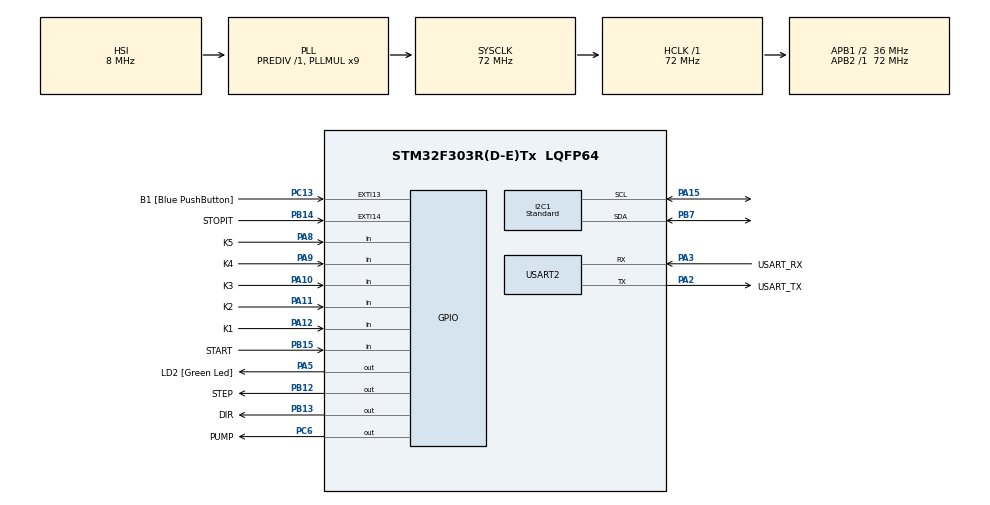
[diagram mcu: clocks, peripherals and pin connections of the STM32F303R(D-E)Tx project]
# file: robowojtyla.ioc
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FREERTOS.Tasks01=defaultTask,24,128,StartDefaultTask,Default,NULL,Dynamic,NULL,NULL;robotOne,24,128,startRobotOne,As external,NULL,Dynamic,NULL,NULL
I2C1.I2C_Speed_Mode=I2C_Standard
Mcu.Family=STM32F3
Mcu.Name=STM32F303R(D-E)Tx
Mcu.Package=LQFP64
NVIC.EXTI15_10_IRQn=true\:5\:0\:false\:false\:true\:true\:true\:true\:true
NVIC.PriorityGroup=NVIC_PRIORITYGROUP_4
NVIC.TIM1_TRG_COM_TIM17_IRQn=true\:15\:0\:false\:false\:true\:false\:false\:true\:true
NVIC.TimeBase=TIM1_TRG_COM_TIM17_IRQn
NVIC.TimeBaseIP=TIM17
PA10.GPIO_Label=K3
PA10.Signal=GPIO_Input
PA11.GPIO_Label=K2
PA11.Signal=GPIO_Input
PA12.GPIO_Label=K1
PA12.Signal=GPIO_Input
PA13.GPIO_Label=TMS
PA13.Mode=Serial_Wire
PA13.Signal=SYS_JTMS-SWDIO
PA14.GPIO_Label=TCK
PA14.Mode=Serial_Wire
PA14.Signal=SYS_JTCK-SWCLK
PA15.Mode=I2C
PA15.Signal=I2C1_SCL
PA2.GPIO_Label=USART_TX
PA2.GPIO_Mode=GPIO_MODE_AF_PP
PA2.GPIO_PuPd=GPIO_NOPULL
PA2.GPIO_Speed=GPIO_SPEED_FREQ_LOW
PA2.Mode=Asynchronous
PA2.Signal=USART2_TX
PA3.GPIO_Label=USART_RX
PA3.GPIO_Mode=GPIO_MODE_AF_PP
PA3.GPIO_PuPd=GPIO_NOPULL
PA3.GPIO_Speed=GPIO_SPEED_FREQ_LOW
PA3.Mode=Asynchronous
PA3.Signal=USART2_RX
PA5.GPIO_Label=LD2 [Green Led]
PA5.GPIO_Mode=GPIO_MODE_OUTPUT_PP
PA5.GPIO_PuPd=GPIO_NOPULL
PA5.GPIO_Speed=GPIO_SPEED_FREQ_LOW
PA5.Signal=GPIO_Output
PA8.GPIO_Label=K5
PA8.Signal=GPIO_Input
PA9.GPIO_Label=K4
PA9.Signal=GPIO_Input
PB12.GPIO_Label=STEP
PB12.Signal=GPIO_Output
PB13.GPIO_Label=DIR
PB13.Signal=GPIO_Output
PB14.GPIO_Label=STOPIT
PB14.Signal=GPXTI14
PB15.GPIO_Label=START
PB15.Signal=GPIO_Input
PB3.GPIO_Label=SWO
PB3.Signal=SYS_JTDO-TRACESWO
PB7.Mode=I2C
PB7.Signal=I2C1_SDA
PC13.GPIO_Label=B1 [Blue PushButton]
PC13.GPIO_ModeDefaultEXTI=GPIO_MODE_IT_FALLING
PC13.Signal=GPXTI13
PC14-OSC32_IN.Mode=LSE-External-Oscillator
PC14-OSC32_IN.Signal=RCC_OSC32_IN
PC15-OSC32_OUT.Mode=LSE-External-Oscillator
PC15-OSC32_OUT.Signal=RCC_OSC32_OUT
PC6.GPIO_Label=PUMP
PC6.Signal=GPIO_Output
PF0-OSC_IN.Mode=HSE-External-Clock-Source
PF0-OSC_IN.Signal=RCC_OSC_IN
PF1-OSC_OUT.Signal=RCC_OSC_OUT
ProjectManager.HeapSize=0x200
ProjectManager.StackSize=0x400
ProjectManager.TargetToolchain=STM32CubeIDE
RCC.AHBFreq_Value=72000000
RCC.APB1CLKDivider=RCC_HCLK_DIV2
RCC.APB1Freq_Value=36000000
RCC.APB1TimFreq_Value=72000000
RCC.APB2Freq_Value=72000000
RCC.APB2TimFreq_Value=72000000
RCC.CortexFreq_Value=72000000
RCC.HCLKFreq_Value=72000000
RCC.HSE_VALUE=8000000
RCC.HSI_VALUE=8000000
RCC.PLLM=8
RCC.PLLMUL=RCC_PLL_MUL9
RCC.PLLN=336
RCC.PLLP=RCC_PLLP_DIV4
RCC.PLLQ=7
RCC.RCC_PLLsource_Clock_Source_FROM_HSE=RCC_HSE_PREDIV_DIV2
RCC.SYSCLKFreq_VALUE=72000000
RCC.SYSCLKSourceVirtual=RCC_SYSCLKSOURCE_PLLCLK
RCC.USBFreq_Value=72000000
USART2.VirtualMode-Asynchronous=VM_ASYNC
VP_FREERTOS_VS_CMSIS_V2.Mode=CMSIS_V2
VP_SYS_VS_tim17.Mode=TIM17
board=NUCLEO-F303RE

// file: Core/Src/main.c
/* USER CODE BEGIN Header */
/**
  ******************************************************************************
  * @file           : main.c
  * @brief          : Main program body
  ******************************************************************************
  * @attention
  *
  * Copyright (c) 2023 STMicroelectronics.
  * All rights reserved.
  *
  * This software is licensed under terms that can be found in the LICENSE file
  * in the root directory of this software component.
  * If no LICENSE file comes with this software, it is provided AS-IS.
  *
  ******************************************************************************
  */
/* USER CODE END Header */
#include "main.h"
#include "cmsis_os.h"
#include "i2c.h"
#include "usart.h"
#include "gpio.h"

void SystemClock_Config(void);
void MX_FREERTOS_Init(void);

int main(void)
{

  /* MCU Configuration--------------------------------------------------------*/

  /* Reset of all peripherals, Initializes the Flash interface and the Systick. */
  HAL_Init();

  /* Configure the system clock */
  SystemClock_Config();

  /* Initialize all configured peripherals */
  MX_GPIO_Init();
  MX_USART2_UART_Init();
  MX_I2C1_Init();
  /* USER CODE BEGIN 2 */
  PCA9685_Init(&hi2c1);
  /* USER CODE END 2 */

  /* Init scheduler */
  osKernelInitialize();

  /* Call init function for freertos objects (in freertos.c) */
  MX_FREERTOS_Init();

  /* Start scheduler */
  osKernelStart();

  /* We should never get here as control is now taken by the scheduler */
  /* Infinite loop */
  while (1)
  {

  }
}

void SystemClock_Config(void)
{
  RCC_OscInitTypeDef RCC_OscInitStruct = {0};
  RCC_ClkInitTypeDef RCC_ClkInitStruct = {0};
  RCC_PeriphCLKInitTypeDef PeriphClkInit = {0};

  /** Initializes the RCC Oscillators according to the specified parameters
  * in the RCC_OscInitTypeDef structure.
  */
  RCC_OscInitStruct.OscillatorType = RCC_OSCILLATORTYPE_HSI;
  RCC_OscInitStruct.HSIState = RCC_HSI_ON;
  RCC_OscInitStruct.HSICalibrationValue = RCC_HSICALIBRATION_DEFAULT;
  RCC_OscInitStruct.PLL.PLLState = RCC_PLL_ON;
  RCC_OscInitStruct.PLL.PLLSource = RCC_PLLSOURCE_HSI;
  RCC_OscInitStruct.PLL.PLLMUL = RCC_PLL_MUL9;
  RCC_OscInitStruct.PLL.PREDIV = RCC_PREDIV_DIV1;
  if (HAL_RCC_OscConfig(&RCC_OscInitStruct) != HAL_OK)
  {
    Error_Handler();
  }

  /** Initializes the CPU, AHB and APB buses clocks
  */
  RCC_ClkInitStruct.ClockType = RCC_CLOCKTYPE_HCLK|RCC_CLOCKTYPE_SYSCLK
                              |RCC_CLOCKTYPE_PCLK1|RCC_CLOCKTYPE_PCLK2;
  RCC_ClkInitStruct.SYSCLKSource = RCC_SYSCLKSOURCE_PLLCLK;
  RCC_ClkInitStruct.AHBCLKDivider = RCC_SYSCLK_DIV1;
  RCC_ClkInitStruct.APB1CLKDivider = RCC_HCLK_DIV2;
  RCC_ClkInitStruct.APB2CLKDivider = RCC_HCLK_DIV1;

  if (HAL_RCC_ClockConfig(&RCC_ClkInitStruct, FLASH_LATENCY_2) != HAL_OK)
  {
    Error_Handler();
  }
  PeriphClkInit.PeriphClockSelection = RCC_PERIPHCLK_USART2|RCC_PERIPHCLK_I2C1;
  PeriphClkInit.Usart2ClockSelection = RCC_USART2CLKSOURCE_PCLK1;
  PeriphClkInit.I2c1ClockSelection = RCC_I2C1CLKSOURCE_HSI;
  if (HAL_RCCEx_PeriphCLKConfig(&PeriphClkInit) != HAL_OK)
  {
    Error_Handler();
  }
}

void HAL_TIM_PeriodElapsedCallback(TIM_HandleTypeDef *htim)
{
  if (htim->Instance == TIM17) {
    HAL_IncTick();
  }
}

void Error_Handler(void)
{
  __disable_irq();
  while (1)
  {
  }
}

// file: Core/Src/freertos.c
/* USER CODE BEGIN Header */
/**
  ******************************************************************************
  * File Name          : freertos.c
  * Description        : Code for freertos applications
  ******************************************************************************
  * @attention
  *
  * Copyright (c) 2023 STMicroelectronics.
  * All rights reserved.
  *
  * This software is licensed under terms that can be found in the LICENSE file
  * in the root directory of this software component.
  * If no LICENSE file comes with this software, it is provided AS-IS.
  *
  ******************************************************************************
  */
/* USER CODE END Header */

#include "FreeRTOS.h"
#include "task.h"
#include "main.h"
#include "cmsis_os.h"

/* Definitions for defaultTask */
osThreadId_t defaultTaskHandle;
const osThreadAttr_t defaultTask_attributes = {
  .name = "defaultTask",
  .stack_size = 128 * 4,
  .priority = (osPriority_t) osPriorityNormal,
};
/* Definitions for robotOne */
osThreadId_t robotOneHandle;
const osThreadAttr_t robotOne_attributes = {
  .name = "robotOne",
  .stack_size = 128 * 4,
  .priority = (osPriority_t) osPriorityNormal,
};
/* Definitions for robotTwo */
osThreadId_t robotTwoHandle;
const osThreadAttr_t robotTwo_attributes = {
  .name = "robotTwo",
  .stack_size = 128 * 4,
  .priority = (osPriority_t) osPriorityNormal,
};
/* Definitions for glassReader */
osThreadId_t glassReaderHandle;
const osThreadAttr_t glassReader_attributes = {
  .name = "glassReader",
  .stack_size = 128 * 4,
  .priority = (osPriority_t) osPriorityLow,
};

void StartDefaultTask(void *argument);
extern void startRobotOne(void *argument);
extern void startRobotTwo(void *argument);
extern void startGlassReader(void *argument);

void MX_FREERTOS_Init(void); /* (MISRA C 2004 rule 8.1) */

void MX_FREERTOS_Init(void) {

  /* Create the thread(s) */
  /* creation of defaultTask */
  defaultTaskHandle = osThreadNew(StartDefaultTask, NULL, &defaultTask_attributes);

  /* creation of robotOne */
  robotOneHandle = osThreadNew(startRobotOne, NULL, &robotOne_attributes);

  /* creation of robotTwo */
  robotTwoHandle = osThreadNew(startRobotTwo, NULL, &robotTwo_attributes);

  /* creation of glassReader */
  glassReaderHandle = osThreadNew(startGlassReader, NULL, &glassReader_attributes);

}

void StartDefaultTask(void *argument)
{
  for(;;)
  {
    osDelay(1);
  }
}

/* USER CODE BEGIN Application */
// TODO rtos task implementation
void startRobotTwo(void *argument){};
void startGlassReader(void *argument){};
/* USER CODE END Application */
